# HR_C7000_DM32 register map
Vendor: Dahua Technology (chip); Baofeng (radio product); Series: HR_C7000; File version: 0.1-dm32re-draft
CPU: other r0p0, little endian, no MPU, no FPU, 0 interrupt priority bits
Registers are 32-bit, read-write, reset 0x0 unless marked. A register's access mark holds for its fields unless they carry their own. Offsets are from the block's base; [hi:lo] are bit positions; {n}, {i} and the like mark numbered series; 'fields as' and 'values as' point back to an identical list.

## USB — Synopsys DesignWare USB 2.0 OTG controller (GSNPSID reads 0x4f54270a), configured device-only with a USB 1.1 full-speed serial transceiver (GUSBCFG.PHYSel=1) (DS §5.6, p.325-377; Register Table 19 is mistitled 'SDIO Register Overview'). IN endpoints 0/1/3 and OUT endpoints 0/2/4 are implemented. FW: no direct access; one base literal at 0x0301f178. The DM-32's USB-C port is not known to carry data.
Base 0x13000000
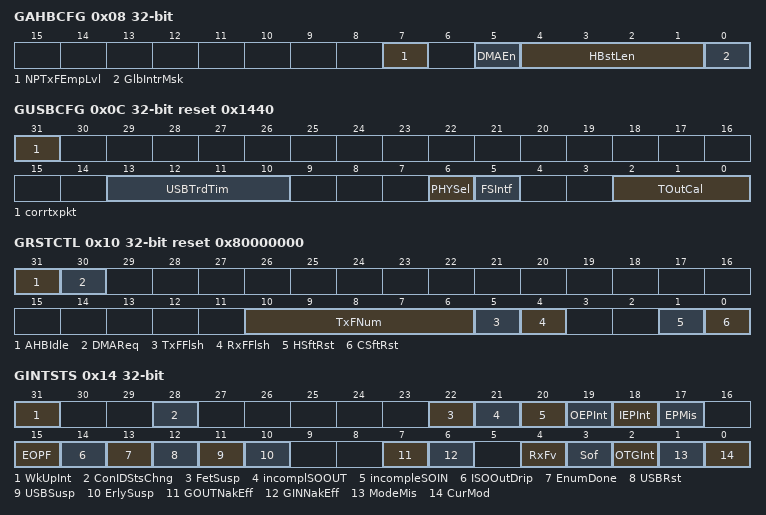
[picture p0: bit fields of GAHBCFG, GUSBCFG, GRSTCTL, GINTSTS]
0x08 GAHBCFG — AHB Configuration , global AHB Configuration. DS §5.6.5.1 p.336. Reset 0x0 (DS).
  [7] NPTxFEmpLvl — Non-Periodic TxFIFO Empty Level , dedicated FIFO In dev mode , 0 : DIENPINTn.TxFEmp indicates that the IN EP TxFIFO is half full. 1 : DIENPINTn.TxFEmp , indicates IN EP TxFIFO is full [reset 0x0] [access RW]
  [5] DMAEn — DMA Enable 0 : Slave mode; 1 : DMA mode [reset 0x0] [access RW]
  [4:1] HBstLen — Burst Length/Type , configure dma_burst[3:0] in DMA mode When internal DMA is configured 4'h0: Single 4'h1: INCR 4'h3: INCR4 4'h5: INCR8 4'h7: INCR16 Other : Reserved [reset 0x0] [access RW]
  [0] GlbIntrMsk — Global Interrupt Mask 0 : Mask all interrupts 1 : Unmask all interrupts [reset 0x0] [access RW]
0x0C GUSBCFG reset 0x1440 — USB Configuration , Global USB Configuration. DS §5.6.5.2 p.338. Reset 0x1440 (DS).
  [31] corrtxpkt — Corrupt Tx Packet Only used in debug mode, do not set it to 1 [reset 0x0] [access RW]
  [13:10] USBTrdTim — USB Turnaround Time Calculation formula: (4*AHB_CLK + 1*PHY_CLK)/PHY_CLK [reset 0x5] [access RW]
  [6] PHYSel ro — USB2.0 HSPHY or USB1.1 FS Serial Transceiver 1 : USB1.1 FS Serial Transceiver 0 : USB2.0 high-speed PHY [reset 0x1] [access RO]
  [5] FSIntf — FS Serial Interace Select 0 : 6-pin unidirectional FS interface 1 : 3-pin bidirectional FS interface [reset 0x0] [access RW]
  [2:0] TOutCal — HS/FS Timeout Calibration (USB defines the FS mode timeout value as 16-18 bits time , which is the delay added to accommodate different PHY delays ) Calculation formula: 0.25bit time * The value [reset 0x0] [access RW]
0x10 GRSTCTL reset 0x80000000 — Reset , global reset control register. DS §5.6.5.3 p.338. Reset 0x80000000 (DS).
  [31] AHBIdle ro — AHB master idle [reset 0x1] [access RO]
  [30] DMAReq ro — DMA request signal (debug) [reset 0x0] [access RO]
  [10:6] TxFNum — TxFIFO number to flush with TxFFlsh: 0 = non-periodic/TxFIFO0, n = TxFIFOn ... 0x10 = all TxFIFOs. Printed FxFNum [reset 0x0] [access RW]
  [5] TxFFlsh write-1-sets — TxFIFO flush; no TxFIFO access may be in progress; wait for self-clear (8 phy_clk or hclk) before the next access [reset 0x0] [access WS/SC]
  [4] RxFFlsh write-1-sets — RxFIFO flush; same rules as TxFFlsh [reset 0x0] [access WS/SC]
  [1] HSftRst write-1-sets — hclk-domain soft reset [reset 0x0] [access WS/SC]
  [0] CSftRst write-1-sets — hclk and phy_clk domain soft reset [reset 0x0] [access WS/SC]
0x14 GINTSTS — Interrupt , global interrupt status register. DS §5.6.5.4 p.340.
  [31] WkUpInt write-1-clears — Resume/Remote Wakeup Dectected interrupt Dev mode: detect USB Set when Resume [reset 0x0] [access RO/WC]
  [28] ConIDStsChng write-1-clears — Connector ID Status Change interrupt [reset 0x0] [access RO/WC]
  [22] FetSusp write-1-clears — Data Fetch Suspended , valid only in DMA mode [reset 0x0] [access RO/WC]
  [21] incomplSOOUT write-1-clears — Incomplete Isochronous OUT Transfer (dev- only) dev mode, there is at least one ISO OUT EP has not completed transmission in the current frame , and is set at the same time as the EOPF interrupt [reset 0x0] [access RO/WC]
  [20] incompleSOIN write-1-clears — Incomplete Isochronous IN Transfer (dev- only) dev mode, there is at least one ISO IN EP has not completed transmission in the current frame , and is set at the same time as the EOPF interrupt [reset 0x0] [access RO/WC]
  [19] OEPInt ro — OUT Endpoints interrupt (dev- only) dev mode, if there is OUT Set when the EP interrupt is not processed. The application must read DAINT and DOEPINTn to determine the specific interrupt event to be processed. [reset 0x0] [access RO]
  [18] IEPInt ro — IN Endpoints interrupt (dev- only) dev mode, if there is IN Set when the EP interrupt is not processed. The application must read DAINT and DIEPINTn to determine the specific interrupt event to be processed. [reset 0x0] [access RO]
  [17] EPMis write-1-clears — Endpoint Mismatch interrupt (dev- only) Only valid when shared FIFO is in operation. After token , FIFO When the data in does not match, it triggers [reset 0x0] [access RO/WC]
  [15] EOPF write-1-clears — End of Periodic Frame interrupt (dev- only) Reach the Periodic value set by DCFG.PerFrInt Frame Triggered when the Interval period is reached [reset 0x0] [access RO/WC]
  [14] ISOOutDrip write-1-clears — ISO OUT Packet Dropped interrupt (dev- only) When the RxFIFO is insufficient and the soft core cannot receive ISO Triggered when OUT packet [reset 0x0] [access RO/WC]
  [13] EnumDone write-1-clears — Enumeration Done interrupt (dev- only) Triggered after speed enumeration is completed. The application must read DSTS to obtain the enumeration result. [reset 0x0] [access RO/WC]
  [12] USBRst write-1-clears — USB Reset interrupt (dev- only) Soft core monitoring to USB Triggered after the reset signal [reset 0x0] [access RO/WC]
  [11] USBSusp write-1-clears — USB Suspend interrupt (dev- only) Triggered after the soft core detects the suspend state [reset 0x0] [access RO/WC]
  [10] ErlySusp write-1-clears — Early Suspend interrupt (dev- only) The soft core is triggered when it detects that the USB bus is in idle state for more than 3ms . [reset 0x0] [access RO/WC]
  [7] GOUTNakEff ro — Global OUT NAK Effective interrupt (dev-only) Triggered when DCTL.SGOUTNak is set, DCTL.CGOUTNak is set Time Clear [reset 0x0] [access RO]
  [6] GINNakEff ro — Global IN Non-periodic NAK Effective interrupt (dev- only) DCTL.SGNPInNak is set, cleared when DCTL.CGNPInNak is set [reset 0x0] [access RO]
  [4] RxFv ro — RxFIFO Non- Empty Triggered when there is at least one packet data waiting to be read in the RxFIFO [reset 0x0] [access RO]
  [3] Sof write-1-clears — Start of Frame Interrupt dev mode, the soft core is triggered when it receives SOF , and the application then reads DSTS Get the frame number [reset 0x0] [access RO/WC]
  [2] OTGInt ro — OTG interrupt Triggered when an OTG protocol event occurs [reset 0x0] [access RO]
  [1] ModeMis write-1-clears — Mode Mismatch interrupt Triggered when the register in dev mode is used as host mode, and the AHB bus responds OKAY , but the soft core ignores the register access operation [reset 0x0] [access RO/WC]
  [0] CurMod ro — Current Mode of Operation 0 : dev , 1 : host [reset 0x0] [access RO]
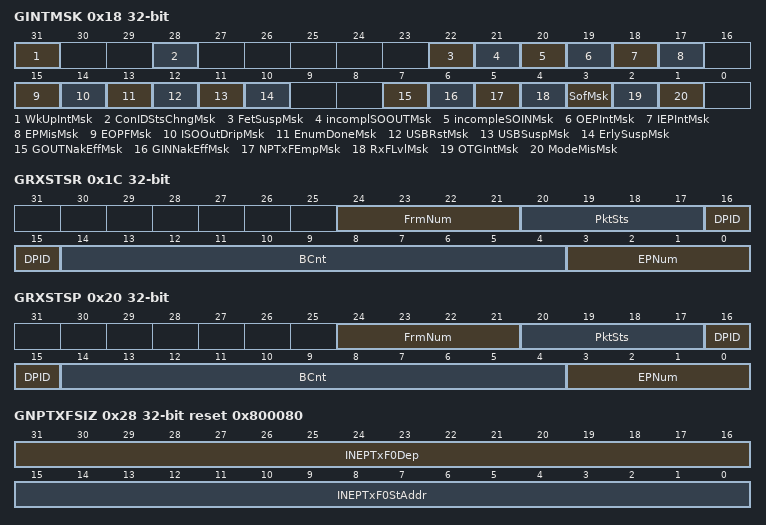
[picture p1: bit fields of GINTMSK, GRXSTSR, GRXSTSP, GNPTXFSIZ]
0x18 GINTMSK — Interrupt Mask , global interrupt mask. DS §5.6.5.5 p.343. Reset 0x0 (DS).
  [31] WkUpIntMsk — Resume/Remote Wakeup Dectected interrupt mask 0 : Shield , 1: Enable (same below ) [reset 0x0] [access RW]
  [28] ConIDStsChngMsk — Connector ID Status Change interrupt mask [reset 0x0] [access RW]
  [22] FetSuspMsk — Data Fetch Suspended interrupt mask, only valid in DMA mode [reset 0x0] [access RW]
  [21] incomplSOOUTMsk — Incomplete Isochronous OUT Transfer interrupt mask (dev-only) [reset 0x0] [access RW]
  [20] incompleSOINMsk — Incomplete Isochronous IN Transfer interrupt mask (dev- only) [reset 0x0] [access RW]
  [19] OEPIntMsk — OUT Endpoints interrupt mask (dev- only) [reset 0x0] [access RW]
  [18] IEPIntMsk — IN Endpoints interrupt mask (dev- only) [reset 0x0] [access RW]
  [17] EPMisMsk — Endpoint Mismatch interrupt (dev- only) [reset 0x0] [access RW]
  [15] EOPFMsk — End of Periodic Frame interrupt mask (dev- only) [reset 0x0] [access RW]
  [14] ISOOutDripMsk — ISO OUT Packet Dropped interrupt mask (dev- only) [reset 0x0] [access RW]
  [13] EnumDoneMsk — Enumeration Done interrupt mask (dev- only) [reset 0x0] [access RW]
  [12] USBRstMsk — USB Reset interrupt mask (dev- only) [reset 0x0] [access RW]
  [11] USBSuspMsk — USB Suspend interrupt mask (dev- only) [reset 0x0] [access RW]
  [10] ErlySuspMsk — Early Suspend interrupt mask (dev- only) [reset 0x0] [access RW]
  [7] GOUTNakEffMsk — Global OUT NAK Effective interrupt mask (dev- only) [reset 0x0] [access RW]
  [6] GINNakEffMsk — Global IN Non-periodic NAK Effective interrupt mask (dev-only) [reset 0x0] [access RW]
  [5] NPTxFEmpMsk — Non-Periodic TxFIFO Empty interrupt mask [reset 0x0] [access RW]
  [4] RxFLvlMsk — RxFIFO Non-Empty Shield [reset 0x0] [access RW]
  [3] SofMsk — Start of Frame interrupt mask [reset 0x0] [access RW]
  [2] OTGIntMsk — OTG interrupt mask [reset 0x0] [access RW]
  [1] ModeMisMsk — Mode Mismatch interrupt mask [reset 0x0] [access RW]
0x1C GRXSTSR ro — DS §5.6.5.6 p.344. Note: GRXSTSP For POP only The header information seems to be not POPable Data information in the package, data information requires POP Corresponding RxFIFO address Reset 0x0 (DS).
  [24:21] FrmNum — Frame Number , ISO The lower four bits of the OUT frame number [reset 0x0] [access RO]
  [20:17] PktSts — Packet Status , indicating the status of the received packet 'h1 : Global OUT NAK ( trigger interrupt ) 'h2 : OUT packet received 'h3 : OUT transmission ends ( trigger interrupt ) 'h4 : SETUP transmission ends ( trigger interrupt ) 'h6 : SETUP packet received Others: Reserved [reset 0x0] [access RO]
  [16:15] DPID — Data PID , indicating the receiving packet status 'h0 : DATA0 'h1 : DATA2 'h2 : DATA1 'h3 : MDATA [reset 0x0] [access RO]
  [14:4] BCnt — Packet Status , indicating the length of the received packet data [reset 0x0] [access RO]
  [3:0] EPNum — Endpoint Number , the destination port number of the current data [reset 0x0] [access RO]
0x20 GRXSTSP ro — DS §5.6.5.6 p.344. Same layout as GRXSTSR; reading GRXSTSP also pops the entry. Note: GRXSTSP For POP only The header information seems to be not POPable Data information in the package, data information requires POP Corresponding RxFIFO address Reset 0x0 (DS).
  fields as GRXSTSR
0x24 GRXFSIZ reset 0x80 — Receive FIFO Size , RxFIFO Allocate control. DS §5.6.5.7 p.346. Reset 0x80 (DS).
  [15:0] RxFDep — RxFIFO depth ( width 35 bits ), min=16 This segment is adjustable according to the actual depth of SPRAM [reset 0x80] [access RW]
0x28 GNPTXFSIZ reset 0x800080 — DS §5.6.5.8 p.346. Reset 0x800080 (DS).
  [31:16] INEPTxF0Dep — IN EP TxFIFO depth ( width 35 bits ), min=16 , depth adjustable [reset 0x80] [access RW]
  [15:0] INEPTxF0StAddr — IN EP TxFIFO start address, adjustable [reset 0x80] [access RW]
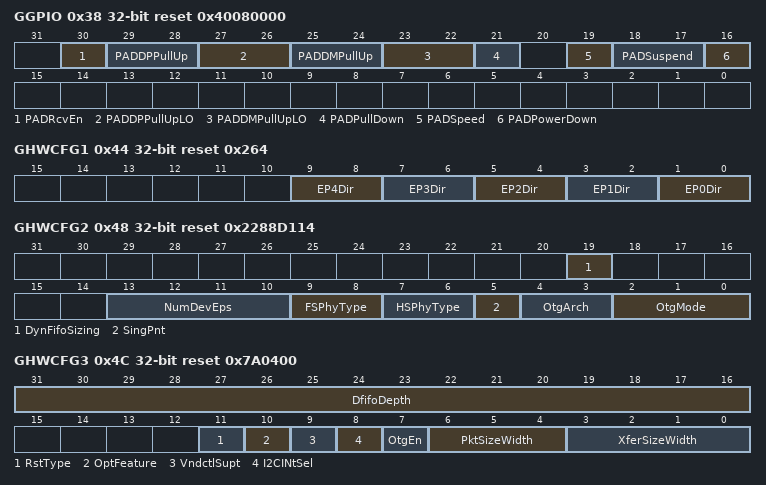
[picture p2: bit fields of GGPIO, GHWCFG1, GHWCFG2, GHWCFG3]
0x38 GGPIO reset 0x40080000 — General Purpose IO , general IO register. DS §5.6.5.9 p.346. Reset 0x40080000 (DS).
  [30] PADRcvEn — PAD differential receive enable 0 : Disable; 1 : Enable [reset 0x1] [access RW]
  [29:28] PADDPPullUp — PAD DP line DPPU control 'h0/1 : soft core dp_rpu1_en signal control 'h2 : Forced pull-up enabled 'h3 : Forced pull-up is invalid [reset 0x0] [access RW]
  [27:26] PADDPPullUpLO — PAD DP line DPPULO control 'h0: soft core dp_rpu2_en signal control 'h1: soft core dp_rpu1_en signal control 'h2 : forced pull- up enable 'h3 : Forced pull-up is invalid [reset 0x0] [access RW]
  [25:24] PADDMPullUp — PAD DM line DMPU control 'h0/1 : soft core dm_rpu_en signal control 'h2 : Forced pull-up enabled 'h3 : Forced pull-up is invalid [reset 0x0] [access RW]
  [23:22] PADDMPullUpLO — PAD DM line DMPULO control 'h0/1 : soft core dm_rpu_en signal control 'h2 : Forced pull-up enabled 'h3 : Forced pull-up is invalid [reset 0x0] [access RW]
  [21] PADPullDown — PAD pull-down resistor control 0 : Pull-down disabled; 1 : Pull-down enabled [reset 0x0] [access RW]
  [19] PADSpeed — PAD rate selection 0 : LS mode; 1: FS mode [reset 0x1] [access RW]
  [18:17] PADSuspend — PAD Suspend Control 'h0/1 : soft core control Suspend signal 'h2 : Forced suspend enabled 'h3 : Forced suspension is invalid [reset 0x0] [access RW]
  [16] PADPowerDown — PAD offline 0 : Power on; 1 : Power off [reset 0x0] [access RW]
0x3C GUID reset 0x45700322 — User ID , user ID register. DS §5.6.5.10 p.348. Reset 0x45700322 (DS).
  [31:0] UserID — User-defined ID number [reset 0x4570_0322] [access RW]
0x40 GSNPSID ro reset 0x4F54270A — Synopsys ID , version number read-only. DS §5.6.5.11 p.348. Reset 0x4f54270a (DS).
  [31:0] SynopsysID — USB soft core version number [reset 0x4f54_270a] [access RO]
0x44 GHWCFG1 ro reset 0x264 — User HW Config1 , soft core configuration. DS §5.6.5.12 p.349. Reset 0x264 (DS).
  [9:8] EP4Dir — EP4 direction: OUT [reset 0x2] [access RO]
  [7:6] EP3Dir — EP3 Direction: IN [reset 0x1] [access RO]
  [5:4] EP2Dir — EP2 direction: OUT [reset 0x2] [access RO]
  [3:2] EP1Dir — EP1 Direction: IN [reset 0x1] [access RO]
  [1:0] EP0Dir — EP0 direction: IN/OUT [reset 0x0] [access RO]
0x48 GHWCFG2 ro reset 0x2288D114 — User HW Config2 , soft core configuration. DS §5.6.5.13 p.349. Reset 0x2288d114 (DS).
  [19] DynFifoSizing — Support dynamic FIFO allocation [reset 0x1] [access RO]
  [13:10] NumDevEps — Supports 4 Dev ports ( except EP0 ) [reset 0x4] [access RO]
  [9:8] FSPhyType — FS PHY interface type: dedicated FS interface [reset 0x1] [access RO]
  [7:6] HSPhyType — HS PHY interface type: HS not supported PHY [reset 0x0] [access RO]
  [5] SingPnt — Point-to-Point ( not used ) [reset 0x0] [access RO]
  [4:3] OtgArch — Soft core architecture: internal DMA [reset 0x2] [access RO]
  [2:0] OtgMode — Working mode: Non-OTG Dev [reset 0x4] [access RO]
0x4C GHWCFG3 ro reset 0x7A0400 — User HW Config3 , soft core configuration. DS §5.6.5.14 p.349. Reset 0x7a0400 (DS).
  [31:16] DfifoDepth — DFIFO effective depth: 122 [reset 0x7a] [access RO]
  [11] RstType — Soft core reset mode: asynchronous reset [reset 0x0] [access RO]
  [10] OptFeature — Remove softcore optional features: No optional features [reset 0x1] [access RO]
  [9] VndctlSupt — Support Vendor Control Interface: Not supported [reset 0x0] [access RO]
  [8] I2CINtSel — Support I2C interface: Not supported [reset 0x0] [access RO]
  [7] OtgEn — Support OTG : No [reset 0x0] [access RO]
  [6:4] PktSizeWidth — Packet counter bit width: 4 bits [reset 0x0] [access RO]
  [3:0] XferSizeWidth — Transfer byte counter bit width: 11 bits [reset 0x0] [access RO]
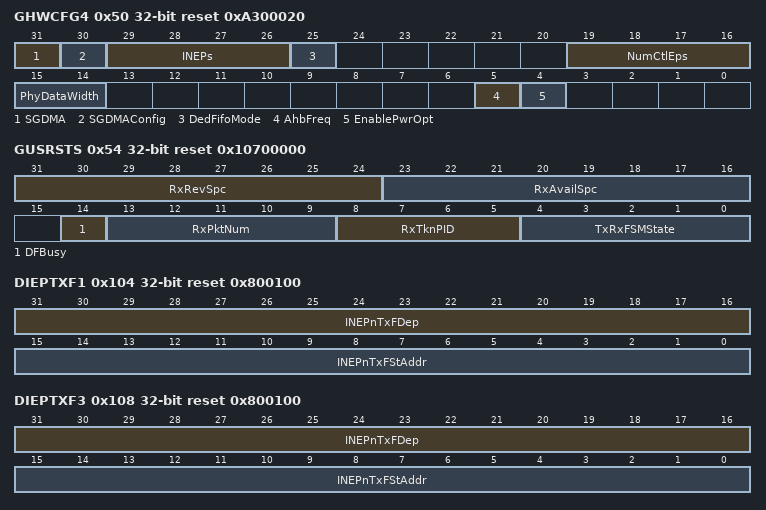
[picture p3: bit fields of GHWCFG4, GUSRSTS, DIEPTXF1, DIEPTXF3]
0x50 GHWCFG4 ro reset 0xA300020 — User HW Config4 , soft core configuration. DS §5.6.5.15 p.351. Reset 0xa300020 (DS).
  [31] SGDMA — Support SG-DMA dynamic configuration: Not supported [reset 0x0] [access RO]
  [30] SGDMAConfig — Is there SG-DMA configuration: No [reset 0x0] [access RO]
  [29:26] INEPs — Supports 3 IN ports ( including EP0 ) [reset 0x2] [access RO]
  [25] DedFifoMode — Dedicated TxFIFO : Yes [reset 0x1] [access RO]
  [19:16] NumCtlEps — Supports 0 control EP number ( except EP0 ) [reset 0x0] [access RO]
  [15:14] PhyDataWidth — PHY interface width: 8 bits [reset 0x0] [access RO]
  [5] AhbFreq — AHB clock greater than 60MHz ? Yes [reset 0x1] [access RO]
  [4] EnablePwrOpt — Support power consumption optimization: Not supported [reset 0x0] [access RO]
0x54 GUSRSTS ro reset 0x10700000 — User States , user-defined observation signals. DS §5.6.5.16 p.351. Reset 0x10700000 (DS).
  [31:24] RxRevSpc — RxFIFO is reserved for CTRL transmission, double word unit [reset 0x10] [access RO]
  [23:16] RxAvailSpc — RxFIFO non- CTRL transmission available space, double word unit [reset 0x70] [access RO]
  [14] DFBusy — FIFO busy 1 : Busy, 0 : Idle [reset 0x0] [access RO]
  [13:9] RxPktNum — Number of packets in RxFIFO [reset 0x0] [access RO]
  [8:5] RxTknPID — Receive packet PID 4′h:1 OUT 4 h2: ACK 4′h3: DATA0 4'h6: SOF 4′h9: IN 4ha: NAK 4 hb: DATA1 4′hc: PRE 4′hd: SETUP 4'he: STALL Ohters: Reserved [reset 0x0] [access RO]
  [4:0] TxRxFSMState — MAC layer state machine current state 5′h0: IDLE 5′h1-5: Not used (Host mode ) 5′h6: Receive Error 5′h7: Receive Data 5′h8: Send Handshake 5′h9: Send EOP 5ha: Send Data 5 hb: Wait Handshake 5 hc: Check CRC16 5 hd: Wait Data 5′he: Test Mode 5′hf: Wait Bus Idle 5′h10: Wait Turnaround 5 h11: Data To Status Others: Reserved [reset 0x0] [access RO]
0x104 DIEPTXF1 reset 0x800100 — DS §5.6.5.17 p.353. IN endpoint 1 TxFIFO size/start. Register Table 19 places DIEPTXF1 at 0x104 and DIEPTXF3 at 0x108 (standard DWC2 would put DIEPTXF3 at 0x10c); the datasheet's offsets are used. Reset start address printed '0x100 / 0x180' for the two instances. Note: For detailed configuration methods, see Section Reset 0x800100 (DS).
  [31:16] INEPnTxFDep — IN EP TxFIFOn depth ( effective bit width 32) , configurable [reset 0x80] [access RW]
  [15:0] INEPnTxFStAddr — IN EP TxFIFOn start address. Reset 0x100 for DIEPTXF1, 0x180 for DIEPTXF3 [reset 0x100] [access RW]
0x108 DIEPTXF3 reset 0x800100 — DS §5.6.5.17 p.353. IN endpoint 3 TxFIFO size/start. Register Table 19 places DIEPTXF1 at 0x104 and DIEPTXF3 at 0x108 (standard DWC2 would put DIEPTXF3 at 0x10c); the datasheet's offsets are used. Reset start address printed '0x100 / 0x180' for the two instances. Note: For detailed configuration methods, see Section Reset 0x800100 (DS).
  fields as DIEPTXF1
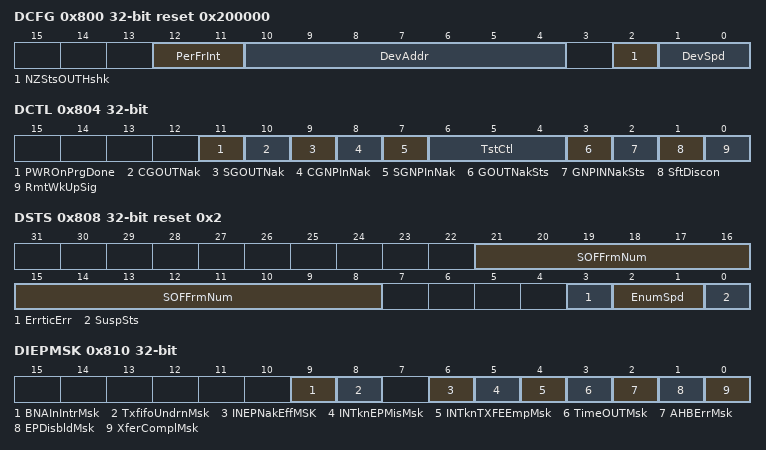
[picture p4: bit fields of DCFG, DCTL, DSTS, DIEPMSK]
0x800 DCFG reset 0x200000 — Device Configuration , device overall. DS §5.6.5.18 p.353. Reset 0x200000 (DS).
  [12:11] PerFrInt — Periodic Frame Interval , from SOF to soft core setting End of Periodic Frame interruption duration 'h0: 80% of the frame interval 'h1: 85% of the frame interval 'h2: 90% of the frame interval [reset 0x0] [access RW]
  [10:4] DevAddr — Dev address, the application software must set it after receiving the SetAddr instruction This paragraph [reset 0x0] [access RW]
  [2] NZStsOUTHshk — Status with non-zero length OUT handshake core 's response mode in the Status Stage when receiving a non-zero length OUT transaction in a control transfer 1 : Respond to the STALL packet and report the data to the application 0 : Report data to the application and respond to the handshake packet according to DCTL.NAK/STALL [reset 0x0] [access RW]
  [1:0] DevSpd — Dev speed 'h0: HS(USB2.0 PHY CLK=30/60MHz) 'h1: FS(USB2.0 PHY CLK=30/60MHz) 'h2: LS(USB1.1 PHY CLK=6MHz) 'h3: FS(USB1.1 PHY CLK = 48MHz) [reset 0x0] [access RW]
0x804 DCTL — Device Control , device overall control. DS §5.6.5.19 p.355. Reset 0x0 (DS).
  [11] PWROnPrgDone — Power-On Programming Done Mark the soft core from power Register configuration is completed after waking up from down mode [reset 0x0] [access RW]
  [10] CGOUTNak wo — Clear Global OUT NAK Clear Global OUT NAK [reset 0x0] [access WO]
  [9] SGOUTNak wo — Set Global OUT NAK When set, all OUT ports in the soft core should NAK packets Before enabling this bit, be sure to clear GINTSTS.GOUTNakEff [reset 0x0] [access WO]
  [8] CGNPInNak wo — Clear Global Non-periodic IN NAK Clear Global Non-periodic IN NAK bit [reset 0x0] [access WO]
  [7] SGNPInNak wo — Set Global Non-periodic IN NAK When set, all IN ports in the soft core should NAK packets Before enabling this bit, be sure to clear GINTSTS.GINNakEff [reset 0x0] [access WO]
  [6:4] TstCtl — Test Controls 'h0 : Test mode is invalid 'h1 : Test J mode 'h2 : Test K mode 'h3 : Test SE0_NAK mode 'h4 : Test Packet mode 'h5 : Test Force_Enable mode Others: Reserved [reset 0x0] [access RW]
  [3] GOUTNakSts ro — Global OUT NAK status 0 : A handshake packet has occurred according to the FIFO status and NAK/STAL settings. 1 : No data is written to RxFIOF . Except for SETUP transactions, all packets Reply NAK and discard all ISO OUT . [reset 0x0] [access RO]
  [2] GNPINNakSts ro — Global Non-periodic IN NAK state 0 : A handshake packet has occurred according to the FIFO status 1 : All non-periodic IN port responds with NAK [reset 0x0] [access RO]
  [1] SftDiscon — Soft Disconnect After setting, the soft core is in a disconnected state and no data interaction occurs. [reset 0x0] [access RW]
  [0] RmtWkUpSig — Remote Wakeup Signaling After setting, the soft core initiates a remote signal to wake up the USB The host application must set this bit to exit the soft core suspend state. According to the USB 2.0 specification, the application must clear this bit 1-15ms after setting it . [reset 0x0] [access RW]
0x808 DSTS ro reset 0x2 — Device Status , device overall status. DS §5.6.5.20 p.357. Reset 0x2 (DS).
  [21:8] SOFFrmNum — Frame Number of Received SOF , receive SOF frame number [reset 0x0] [access RO]
  [3] ErrticErr — Uncertain error UTMI PHY status error reports this error, and the software enters the suspended state, and GINTSTS.ErlySusp is set. At this time, the application software can only be restored through soft disconnect [reset 0x0] [access RO]
  [2:1] EnumSpd — Enumerated Speed , indicating the operating frequency after the soft core is powered on and enumerated. 'h0: HS (USB2.0 PHY CLK=30/60MHz) 'h1: FS(USB2.0 PHY CLK=30/60MHz) 'h2: LS(USB1.1 PHY CLK=6MHz) 'h3: FS(USB1.1 PHY CLK = 48MHz) [reset 0x1] [access RO]
  [0] SuspSts — Suspend Status Dev mode, the soft core detects a suspend condition and sets the bit. The soft core then enters the suspend state. The soft core exits the suspend state under any of the following conditions: • There is a level change on the phy_lin_state_i signal line; • DCTL.RmtWkUpSig is set [reset 0x0] [access RO]
0x810 DIEPMSK — equipment. DS §5.6.5.21 p.358. Reset 0x0 (DS).
  [9] BNAInIntrMsk — Buffer Not Available interrupt mask, 0 : mask , 1: enable (same below ) [reset 0x0] [access RW]
  [8] TxfifoUndrnMsk — FIFO Underrun Shield [reset 0x0] [access RW]
  [6] INEPNakEffMSK — IN Endpoint NAK Effective Mask [reset 0x0] [access RW]
  [5] INTknEPMisMsk — IN Token received with EP Mismatch Mask [reset 0x0] [access RW]
  [4] INTknTXFEEmpMsk — IN Token Received When TxFIFO Empty Mask [reset 0x0] [access RW]
  [3] TimeOUTMsk — Timeout Condition Mask [reset 0x0] [access RW]
  [2] AHBErrMsk — AHB Error Mask , valid for DMA [reset 0x0] [access RW]
  [1] EPDisbldMsk — Endpoint Disabled Interrupt Mask [reset 0x0] [access RW]
  [0] XferComplMsk — Transfer Completed Interrupt Mask [reset 0x0] [access RW]
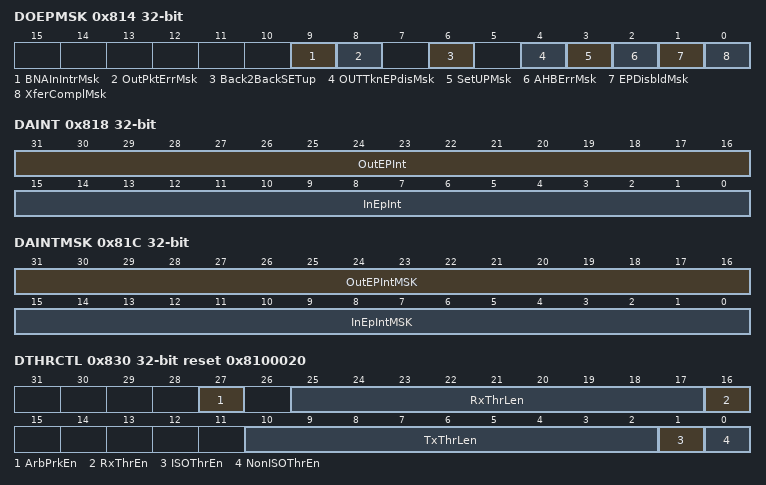
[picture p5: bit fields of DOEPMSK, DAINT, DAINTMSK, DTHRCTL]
0x814 DOEPMSK — DS §5.6.5.22 p.359. Reset 0x0 (DS).
  [9] BNAInIntrMsk — BNA interrupt mask, 0 : mask , 1: enable (same below ) [reset 0x0] [access RW]
  [8] OutPktErrMsk — OUT Packet Error Mask [reset 0x0] [access RW]
  [6] Back2BackSETup — Back-to-Back Packets Received Mask [reset 0x0] [access RW]
  [4] OUTTknEPdisMsk — OUT Token Received when Endpoint Disabled mask [reset 0x0] [access RW]
  [3] SetUPMsk — SETUP Phase Done Mask , only used for control ports [reset 0x0] [access RW]
  [2] AHBErrMsk — AHB Error Mask [reset 0x0] [access RW]
  [1] EPDisbldMsk — Endpoint Disabled Interrupt Mask [reset 0x0] [access RW]
  [0] XferComplMsk — Transfer Completed Interrupt Mask [reset 0x0] [access RW]
0x818 DAINT ro — the device. DS §5.6.5.23 p.359. Reset 0x0 (DS).
  [31:16] OutEPInt — Each bit indicates an OUT port bit16 : OUT EP0 bit31 : OUT EP15 [reset 0x0] [access RO]
  [15:0] InEpInt — Each bit indicates an IN port bit0 : IN EP0 bit15 : IN EP15 [reset 0x0] [access RO]
0x81C DAINTMSK ro — DS §5.6.5.24 p.360. Reset 0x0 (DS).
  [31:16] OutEPIntMSK — Each bit indicates an OUT port, 0 : shield , 1: enable (same below) bit16 : OUT EP0 bit31 : OUT EP15 [reset 0x0] [access RO]
  [15:0] InEpIntMSK — Each bit indicates an IN port bit0 : IN EP0 bit15 : IN EP15 [reset 0x0] [access RO]
0x830 DTHRCTL reset 0x8100020 — Device Threshold Control , device threshold. DS §5.6.5.25 p.360. Reset 0x8100020 (DS).
  [27] ArbPrkEn — Arbiter Parking Enable Controls arbitration of the internal DMA pause IN port [reset 0x1] [access RW]
  [25:17] RxThrLen — Receive Threshold Length Receive threshold, minimum value is 8 DWord (32bit) [reset 0x8] [access RW]
  [16] RxThrEn — Receive Threshold Enable Receive threshold enable [reset 0x0] [access RW]
  [10:2] TxThrLen — TransmitThreshold Length Send threshold, minimum value is 8 DWord (32bit) [reset 0x8] [access RW]
  [1] ISOThrEn — ISO IN Endpoints Threshold Enable ISO IN port receive threshold enable [reset 0x0] [access RW]
  [0] NonISOThrEn — Non-ISO IN Endpoints Threshold Enable Non- ISO IN port receive threshold enable [reset 0x0] [access RW]
0x834 DIEPEMPMSK ro — DS §5.6.5.26 p.360. Reset 0x0 (DS).
  [15:0] InEpTxfEmpMsk — One bit per IN endpoint (bit 0 = IN EP0 ... bit 15 = IN EP15), controls whether DIEPINTn.TxFEmp raises an interrupt. Printed in Chinese: 每个位标示一个IN端口，用于控制DIEPINTn.TxfEmp [reset 0x0] [access RO]
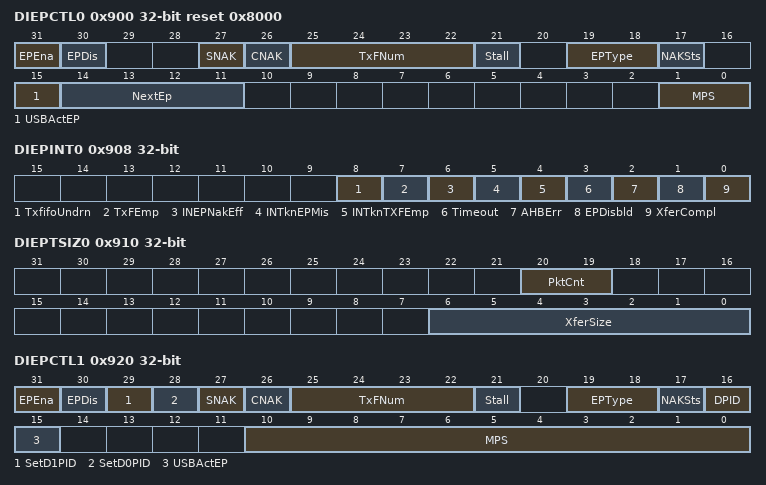
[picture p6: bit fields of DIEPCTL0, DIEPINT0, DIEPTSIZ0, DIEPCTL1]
0x900 DIEPCTL0 reset 0x8000 — EP0. DS §5.6.5.27 p.361. Reset 0x8000 (DS).
  [31] EPEna write-1-sets — Endpoint Enable In non- SG-DMA mode, when set, indicates data is ready. The soft core automatically clears this bit before asserting any of the following interrupts: endpoint disable transfer completed [reset 0x0] [access WS/SC]
  [30] EPDis write-1-sets — Endpoint diable , can only be used after setting EPEna When set, it forces the data transmission to be terminated ( even if the data has not yet ended ) . The soft core automatically clears this bit before setting the Endpoint disable interrupt. [reset 0x0] [access WS/SC]
  [27] SNAK wo — Set NAK When set, the control port responds with NAK [reset 0x0] [access WO]
  [26] CNAK wo — Clear NAK , clear the SNAK bit [reset 0x0] [access WO]
  [25:22] TxFNum — Specify a dedicated TxFIFO number Indicates allocation to IN EP0 TxFIFO number, must be zero [reset 0x0] [access RW]
  [21] Stall write-1-sets — Stall handshake The application can only set this bit after receiving the SETUP signaling. This bit has higher priority than NAK , Global Non-Periodic IN NAK and Global OUT NAK bits. [reset 0x0] [access WS/SC]
  [19:18] EPType ro — Port type, EP0 is only used for control [reset 0x0] [access RO]
  [17] NAKSts ro — NAK status 0 : The soft core sends a non-NAK handshake packet based on the FIFO status 1 : The soft core sends a NAK handshake packet When set, the soft core forces the termination of data transfer [reset 0x0] [access RO]
  [15] USBActEP ro — USB Active port, EP0 is always active [reset 0x1] [access RO]
  [14:11] NextEp — Next port ( only for shared FIFO configuration, [reset 0x0] [access RW]
  [1:0] MPS — Maximum Packet Size 'h0: 64 bytes 'h1 : 32 bytes 'h2 : 16 bytes 'h3: 8 bytes [reset 0x0] [access RW]
0x908 DIEPINT0 — DS §5.6.5.28 p.363. Endpoint 0 instance of DIEPINT0/1/3 (stride 0x20). Reset 0x0 (DS).
  [8] TxfifoUndrn write-1-clears — Set DATA1 PID , IN Only valid in configurations with dedicated TxFIFO and threshold [reset 0x0] [access RO/WC]
  [7] TxFEmp ro — TxFIFO Empty when the TxFIFO is half empty or completely empty. GAHBCFG.NPTXFempLvl determines whether the interrupt is half-empty or full-empty. [reset 0x0] [access RO]
  [6] INEPNakEff write-1-clears — IN Endpoint NAK Effective the soft core detects that NAK is set, the interrupt is triggered. DIEPCTLn.CNAK clears the interrupt [reset 0x0] [access RO/WC]
  [5] INTknEPMis — Receive IN that does not match EP Token (non- periodic valid ) The port receives IN Token , non-periodic Triggered when the data at the TxFIFO output port is not the EP [reset 0x0] [access -]
  [4] INTknTXFEmp write-1-clears — Receive IN Token TxFIFO empty ( non-periodic valid ) receiving the IN command, the TxFIFO of the corresponding EP is empty. [reset 0x0] [access RO/WC]
  [3] Timeout write-1-clears — Timeout Condition , the applicable conditions are as follows: DitedcaTxFIFO configuration : CTRL The soft core is triggered after detecting that the last IN instruction of USB has timed out. [reset 0x0] [access RO/WC]
  [2] AHBErr write-1-clears — AHB Error In internal DMA mode, trigger when AHB read or write error occurs [reset 0x0] [access RO/WC]
  [1] EPDisbld write-1-clears — Endpoint Disable Triggered when the port is closed [reset 0x0] [access RO/WC]
  [0] XferCompl write-1-clears — Transfer Complete Triggered when the specified number of transfers have completed [reset 0x0] [access RO/WC]
0x910 DIEPTSIZ0 — Device IN Endpoint0 Transfer Size , device IN. DS §5.6.5.29 p.363. Reset 0x0 (DS).
  [20:19] PktCnt — Packet Count EP0 The number of USB packets in this transaction . After the soft core sends a packet to the TxFIFO , the segment is automatically reduced by 1. [reset 0x0] [access RW]
  [6:0] XferSize — Transfer Size The total byte length of this transaction of EP0 , that is, the sum of the lengths of PktCnt packets. After the soft core pushes the sent data into TxFIFO , the value of this segment is automatically reduced by 1 . it reaches 0 , the transfer completion interrupt is triggered. [reset 0x0] [access RW]
0x914 DIEPDMA0 — DS §5.6.5.30 p.365. Endpoint 0 instance of DIEPDMA0/1/3 (stride 0x20). Reset 0x0 (DS).
  [31:0] DMAAddr — EP0 IN DMA address [reset 0x0] [access RW]
0x918 DTXFSTS0 ro — DS §5.6.5.31 p.365. Endpoint 0 instance of DTXFSTS0/1/3 (stride 0x20). Reset 0x0 (DS).
  [15:0] InEpTxFSpcAvail — The corresponding port TxFIFO space is available 'h0 ： EP0 TxFIFO full 'h1 : remaining 1 word … 'hn : remainder n words(0 ≤ n ≤ 32768) 'h8000 : 32768 words remaining Others: Reserved [reset 0x0] [access RO]
0x920 DIEPCTL1 — DS §5.6.5.36 p.369. Endpoint 1 instance of DIEPCTL1/3 (stride 0x20). Reset 0x0 (DS).
  [31] EPEna write-1-sets — Endpoint Enable Set to indicate that the data is ready to be sent, and the soft core automatically clears this bit before setting any of the following interrupts Endpoint disable Transfer completed [reset 0x0] [access WS/SC]
  [30] EPDis write-1-sets — Endpoint Disable When set, it forces the termination of data transmission ( even if the data has not yet ended ) , and the soft core automatically clears this bit before setting the Endpoint disable interrupt. be used after setting EPEna [reset 0x0] [access WS/SC]
  [29] SetD1PID wo — Set DATA1 PID Set port Data PID value is set to DATA1 [reset 0x0] [access WO]
  [28] SetD0PID wo — Set DATA0 PID Set port Data PID value is set to DATA0 [reset 0x0] [access WO]
  [27] SNAK wo — Set NAK When set, the control port responds with NAK [reset 0x0] [access WO]
  [26] CNAK wo — Clear NAK , IN/OUT Clear the SNAK bit [reset 0x0] [access WO]
  [25:22] TxFNum — Specify a dedicated TxFIFO number Configure mapping to EP1 IN and EP3 IN TxFIFO number DIEPCTL1.TxFNum = 0x1 DIEPCTL3.TxFNum = 0x2 [reset 0x0] [access RW]
  [21] Stall — Stall handshake ( valid in non-ISO ) After setting, the port only responds to STALL . This bit has higher priority than NAK , Global Non-Periodic IN NAK and Global OUT NAK bit, the application should clear this bit. [reset 0x0] [access RW]
  [19:18] EPType ro — Port transmission type 'h0 : Control ( not supported ) 'h1: ISO 'h2: Bulk 'h3: Intr [reset 0x0] [access RO]
  [17] NAKSts ro — NAK status 0 : The soft core sends a non-NAK handshake packet based on the FIFO status 1 : The soft core sends a NAK handshake packet When set, data is transferred as follows: Non-ISO IN port: The soft core is forced to stop sending any data; ISO IN port: The soft core sends a zero-length data packet; [reset 0x0] [access RO]
  [16] DPID ro — Endpoint Data PID (Intr/Bulk valid ) PID information of the packet that the port is about to receive / send . After the port is enabled, the application must set the SetD0PID or SetD1PID information for a receive / send packet . 0 : DATA0 , 1 : DATA1 [reset 0x0] [access RO]
  [15] USBActEP — USB Active Endpoint Indicates whether the port is active under the current configuration and interface descriptor. The application must determine whether to configure this bit based on the SetConfiguration and SetInterface instructions. The soft core detects the USB This bit is automatically cleared after reset [reset 0x0] [access RW/SC]
  [10:0] MPS — Maximum Packet Size The software must write the maximum packet length in bytes to this section. [reset 0x0] [access RW]
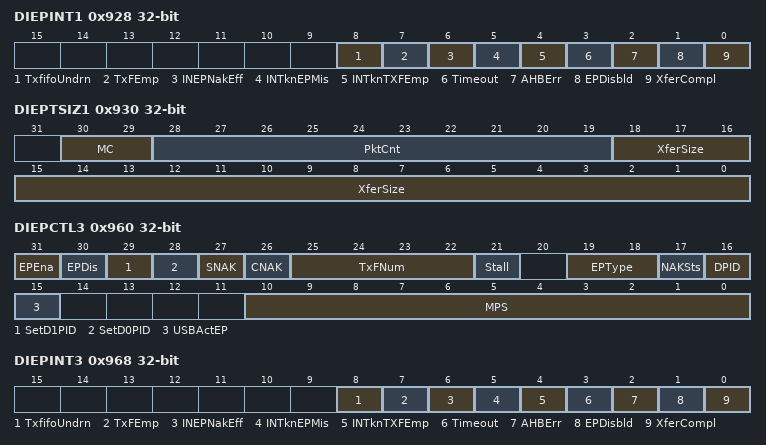
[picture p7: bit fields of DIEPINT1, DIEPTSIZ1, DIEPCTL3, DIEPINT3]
0x928 DIEPINT1 — DS §5.6.5.28 p.363. Endpoint 1 instance of DIEPINT0/1/3 (stride 0x20). Reset 0x0 (DS).
  fields as DIEPINT0
0x930 DIEPTSIZ1 — DS §5.6.5.37 p.373. Endpoint 1 instance of DIEPTSIZ1/3 (stride 0x20). Reset 0x0 (DS).
  [30:29] MC — Multi Count For the Periodic IN port, this field specifies the number of ISO packets per frame . The soft core uses this value to calculate the ISO data PID . 'h1: 1 , 'h2: 2, 'h3: 3 For non-periodic IN ports (RO) , this field is used only in internal DMA mode. This field specifies the number of packets that the soft core must prepare for the current EP before switching to the next EP . [reset 0x0] [access RW]
  [28:19] PktCnt — Packet Count Specify the number of transaction packets. When TxFIFO sends a packet, the segment is automatically decremented. [reset 0x0] [access RW]
  [18:0] XferSize — Transfer Size The total byte length of this transaction on the port. Every time a byte is written to the TxFIFO , the segment is automatically reduced by 1 and an interrupt is triggered when it reaches zero. [reset 0x0] [access RW]
0x934 DIEPDMA1 — DS §5.6.5.30 p.365. Endpoint 1 instance of DIEPDMA0/1/3 (stride 0x20). Reset 0x0 (DS).
  [31:0] DMAAddr — EP0 IN DMA address [reset 0x0] [access RW]
0x938 DTXFSTS1 ro — DS §5.6.5.31 p.365. Endpoint 1 instance of DTXFSTS0/1/3 (stride 0x20). Reset 0x0 (DS).
  fields as DTXFSTS0
0x960 DIEPCTL3 — DS §5.6.5.36 p.369. Endpoint 3 instance of DIEPCTL1/3 (stride 0x20). Reset 0x0 (DS).
  fields as DIEPCTL1
0x968 DIEPINT3 — DS §5.6.5.28 p.363. Endpoint 3 instance of DIEPINT0/1/3 (stride 0x20). Reset 0x0 (DS).
  fields as DIEPINT0
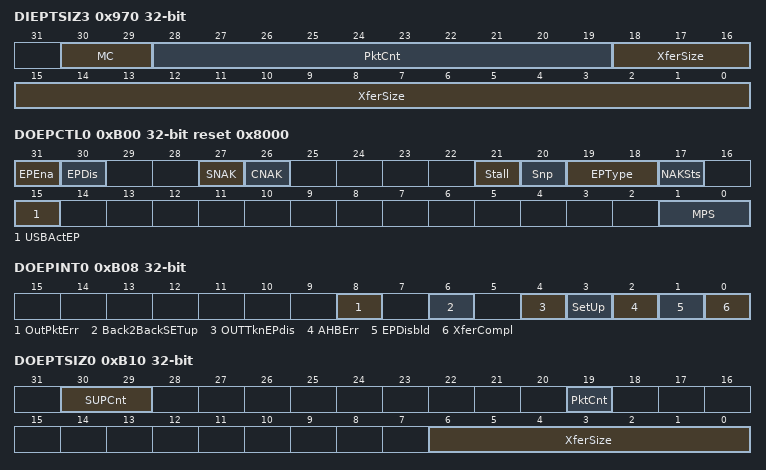
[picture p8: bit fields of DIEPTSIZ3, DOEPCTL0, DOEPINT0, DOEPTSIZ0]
0x970 DIEPTSIZ3 — DS §5.6.5.37 p.373. Endpoint 3 instance of DIEPTSIZ1/3 (stride 0x20). Reset 0x0 (DS).
  fields as DIEPTSIZ1
0x974 DIEPDMA3 — DS §5.6.5.30 p.365. Endpoint 3 instance of DIEPDMA0/1/3 (stride 0x20). Reset 0x0 (DS).
  [31:0] DMAAddr — EP0 IN DMA address [reset 0x0] [access RW]
0x978 DTXFSTS3 ro — DS §5.6.5.31 p.365. Endpoint 3 instance of DTXFSTS0/1/3 (stride 0x20). Reset 0x0 (DS).
  fields as DTXFSTS0
0xB00 DOEPCTL0 reset 0x8000 — DS §5.6.5.32 p.365. Reset 0x8000 (DS).
  [31] EPEna write-1-sets — Endpoint Enable In non- SG-DMA mode, when set, it indicates that the FIFO allocation is ready to receive Host data. The soft core automatically clears this bit before setting any of the following interrupts: SETUP Phase Done Transfer Completed Endpoint Disable ( illegal ) [reset 0x0] [access WS/SC]
  [30] EPDis ro — Endpoint diable , OUT EP0 is always in a valid state and cannot be disabled. effect [reset 0x0] [access RO]
  [27] SNAK wo — Set NAK When set, the control port responds with NAK [reset 0x0] [access WO]
  [26] CNAK wo — Clear NAK , clear the SNAK bit [reset 0x0] [access WO]
  [21] Stall write-1-sets — Stall handshake The application can only set this bit after receiving the SETUP signaling. This bit has a higher priority than NAK and Global OUT NAK bits. [reset 0x0] [access WS/SC]
  [20] Snp — Snoop Mode In Snoop mode, the soft core does not check whether the OUT packet is correct, but directly reports it to the application [reset 0x0] [access RW]
  [19:18] EPType ro — Port type, EP0 is only used for control [reset 0x0] [access RO]
  [17] NAKSts ro — NAK status 0 : The soft core sends a non-NAK handshake packet based on the FIFO status 1 : The soft core sends a NAK handshake packet When set, the soft core forces the termination of data transfer [reset 0x0] [access RO]
  [15] USBActEP ro — USB Active port, EP0 is always active [reset 0x1] [access RO]
  [1:0] MPS ro — Maximum Packet Size , same as DIEPCTL0.MPS'h0 : 64 bytes 'h1 : 32 bytes 'h2 : 16 bytes 'h3: 8 bytes [reset 0x0] [access RO]
0xB08 DOEPINT0 — DS §5.6.5.33 p.367. Endpoint 0 instance of DOEPINT0/2/4 (stride 0x20). Reset 0x0 (DS).
  [8] OutPktErr write-1-clears — OUT Packet Error Only valid in configurations with dedicated TxFIFO and threshold [reset 0x0] [access RO/WC]
  [6] Back2BackSETup write-1-clears — Back2BackSETup (CTRL is valid ) the soft core receives three or more consecutive SETUP packets [reset 0x0] [access RO/WC]
  [4] OUTTknEPdis write-1-clears — OUT Token Received when EP Disa (CTRL valid ) OUT is received , EP is not enabled yet [reset 0x0] [access RO/WC]
  [3] SetUp write-1-clears — SETUP Phase DONE (CTRL is valid ) SETUP Triggered when the Stage is completed and there are no subsequent SETUP packets. After this interrupt, the application can start parsing the SETUP packet. [reset 0x0] [access RO/WC]
  [2] AHBErr write-1-clears — AHB Error In internal DMA mode, trigger when AHB read or write error occurs [reset 0x0] [access RO/WC]
  [1] EPDisbld write-1-clears — Endpoint Disable Triggered when the port is closed [reset 0x0] [access RO/WC]
  [0] XferCompl write-1-clears — Transfer Complete The specified number of transfers has completed [reset 0x0] [access RO/WC]
0xB10 DOEPTSIZ0 — OUT. DS §5.6.5.34 p.369. Reset 0x0 (DS).
  [30:29] SUPCnt — SETUP Packet Count SETUP packets that the port can accept . After the soft core reads a packet from the RxFIFO , this segment is automatically reduced by 1. 'h1: 1 , 'h2: 2, 'h3: 3 [reset 0x0] [access RW]
  [19] PktCnt — Packet Count EP0 The number of USB packets in this transaction . After the soft core reads a packet from the RxFIFO , this segment is automatically reduced to 0. [reset 0x0] [access RW]
  [6:0] XferSize — Transfer Size EP0 total byte length of this transaction. After the soft core receives a byte and reads it from the RxFIFO , the value of this segment automatically decreases by 1. When it decreases to 0 , the transmission completion interrupt is triggered. [reset 0x0] [access RW]
0xB14 DOEPDMA0 — DS §5.6.5.35 p.369. Endpoint 0 instance of DOEPDMA0/2/4 (stride 0x20). Reset 0x0 (DS).
  [31:0] DMAAddr — EP0 OUT DMA Address [reset 0x0] [access RW]
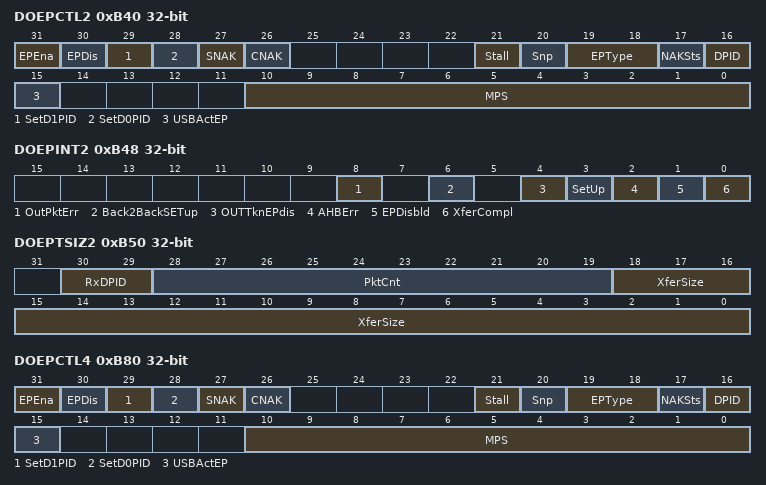
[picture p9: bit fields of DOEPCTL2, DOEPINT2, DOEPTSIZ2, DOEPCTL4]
0xB40 DOEPCTL2 — DS §5.6.5.38 p.373. Endpoint 2 instance of DOEPCTL2/4 (stride 0x20). Reset 0x0 (DS).
  [31] EPEna write-1-sets — Endpoint Enable When set, indicates data is ready. The soft core automatically clears this bit before asserting any of the following interrupts: Endpoint disable Transfer completed [reset 0x0] [access WS/SC]
  [30] EPDis write-1-sets — Endpoint disable When set, it forces the data transfer to terminate ( even if the data has not yet ended ) . The soft core automatically clears this bit before setting the Endpoint Disable interrupt. be used after setting EPEna [reset 0x0] [access WS/SC]
  [29] SetD1PID wo — Set DATA1 PID (Intr/Bulk valid ) Set port Data PID value is set to DATA1 [reset 0x0] [access WO]
  [28] SetD0PID wo — Set DATA0 PID (INT/Bulk valid ) Set port Data PID value is set to DATA0 [reset 0x0] [access WO]
  [27] SNAK wo — Set NAK When set, the control port responds with NAK [reset 0x0] [access WO]
  [26] CNAK wo — Clear NAK Clear the SNAK bit [reset 0x0] [access WO]
  [21] Stall — Stall handshake ( valid for Non-ISO/CTRL ) After setting, the port only responds to STALL . This bit has higher priority than NAK , Global Non-Periodic IN NAK and Global OUT NAK bit, the application should clear this bit. [reset 0x0] [access RW]
  [20] Snp — Snoop Mode In Snoop mode, the soft core does not check whether the OUT packet is correct, but directly reports it to the application [reset 0x0] [access RW]
  [19:18] EPType ro — Port transfer type 'h0: Control 'h1: ISO 'h2: Bulk 'h3: Int [reset 0x0] [access RO]
  [17] NAKSts ro — NAK status 0 : The soft core sends a non-NAK handshake packet based on the FIFO status 1 : The soft core sends a NAK handshake packet When set, data is transferred as follows: OUT port: The soft core is forced to stop receiving any data; [reset 0x0] [access RO]
  [16] DPID ro — Endpoint Data PID (Intr/Bulk valid ) PID information of the packet that the port is about to receive / send . After the port is enabled, the application must set the SetD0PID or SetD1PID information for a receive / send packet . 0 : DATA0 , 1 : DATA1 [reset 0x0] [access RO]
  [15] USBActEP — USB Active Endpoint Indicates whether the port is active under the current configuration and interface descriptor. The application must determine whether to configure this bit based on the SetConfiguration and SetInterface instructions. The soft core detects the USB This bit is automatically cleared after reset [reset 0x0] [access RW/SC]
  [10:0] MPS — Maximum Packet Size The software must write the maximum packet length in bytes to this section. [reset 0x0] [access RW]
0xB48 DOEPINT2 — DS §5.6.5.33 p.367. Endpoint 2 instance of DOEPINT0/2/4 (stride 0x20). Reset 0x0 (DS).
  fields as DOEPINT0
0xB50 DOEPTSIZ2 — DS §5.6.5.39 p.376. Endpoint 2 instance of DOEPTSIZ2/4 (stride 0x20). Reset 0x0 (DS).
  [30:29] RxDPID ro — Received Data PID (ISO valid ) PID number of the last packet 'h0: DATA0 'h1: DATA2 'h2: DATA1 'h3: MDATA [reset 0x0] [access RO]
  [28:19] PktCnt — Packet Count Specify the number of transaction packets. When RxFIFO receives a packet, the segment is automatically reduced by 1. [reset 0x0] [access RW]
  [18:0] XferSize — Transfer Size The total byte length of this transaction on the port. Each time a byte is read from the RxFIFO , the segment is automatically reduced by 1 and an interrupt is triggered when it reaches zero. [reset 0x0] [access RW]
0xB54 DOEPDMA2 — DS §5.6.5.35 p.369. Endpoint 2 instance of DOEPDMA0/2/4 (stride 0x20). Reset 0x0 (DS).
  [31:0] DMAAddr — EP0 OUT DMA Address [reset 0x0] [access RW]
0xB80 DOEPCTL4 — DS §5.6.5.38 p.373. Endpoint 4 instance of DOEPCTL2/4 (stride 0x20). Reset 0x0 (DS).
  fields as DOEPCTL2
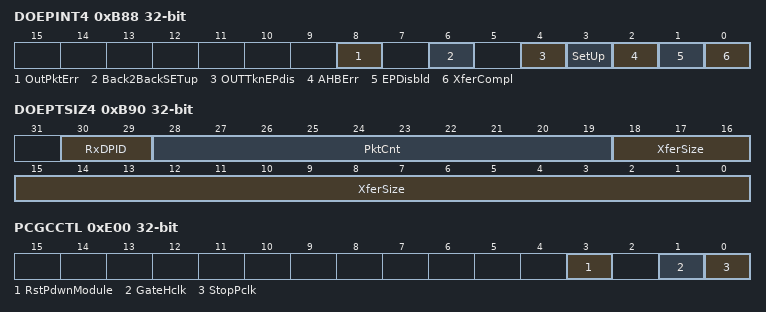
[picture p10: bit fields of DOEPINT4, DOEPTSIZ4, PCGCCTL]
0xB88 DOEPINT4 — DS §5.6.5.33 p.367. Endpoint 4 instance of DOEPINT0/2/4 (stride 0x20). Reset 0x0 (DS).
  fields as DOEPINT0
0xB90 DOEPTSIZ4 — DS §5.6.5.39 p.376. Endpoint 4 instance of DOEPTSIZ2/4 (stride 0x20). Reset 0x0 (DS).
  fields as DOEPTSIZ2
0xB94 DOEPDMA4 — DS §5.6.5.35 p.369. Endpoint 4 instance of DOEPDMA0/2/4 (stride 0x20). Reset 0x0 (DS).
  [31:0] DMAAddr — EP0 OUT DMA Address [reset 0x0] [access RW]
0xE00 PCGCCTL — gating. DS §5.6.5.40 p.377. Reset 0x0 (DS).
  [3] RstPdwnModule — Reset Power-Down Modules is only valid in partial power-down mode . The application is set after the power is turned off and the power is turned on and the PHY This bit is cleared after the clock starts. [reset 0x0] [access RW]
  [1] GateHclk — Gate Hclk When USB is suspended, the application can set this bit to turn off hclk [reset 0x0] [access RW]
  [0] StopPclk — Stop Pclk When Dev is in suspend or disconnect state, the application software can set this bit to turn off phy_clk [reset 0x0] [access RW]
{0x1000+0x1000*i} DEVEP{i}FF (i=0..4) — DS §5.6.4 p.334. Endpoint {i} data FIFO push/pop window (4 KB at {0x1000+0x1000*i}). Listed in Register Table 19 only.
